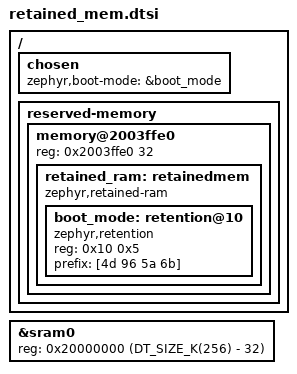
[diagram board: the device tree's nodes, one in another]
/*
 * Copyright (c) Arduino s.r.l. and/or its affiliated companies
 *
 * SPDX-License-Identifier: Apache-2.0
 */

/*
 * Warm-reset retained RAM shared by MCUboot and the loader/sketch; both
 * overlays in this directory include it, so the addresses cannot drift.
 *
 *   0x00  double-tap cookie, MCUboot only (boot/arduino/hooks/hooks.c)
 *   0x10  boot_mode, set by a double tap or the 1200-bps touch and consumed
 *         by CONFIG_BOOT_USB_DFU_BOOT_MODE
 *
 * sram0 is shrunk by the region's size so neither image's linker allocates
 * into it; outside .bss and .data it survives a warm reset.
 */
&sram0 {
	reg = <0x20000000 (DT_SIZE_K(256) - 32)>;
};

/ {
	chosen {
		zephyr,boot-mode = &boot_mode;
	};

	reserved-memory {
		#address-cells = <1>;
		#size-cells = <1>;
		ranges;

		memory@2003ffe0 {
			reg = <0x2003ffe0 32>;

			retained_ram: retainedmem {
				compatible = "zephyr,retained-ram";
				status = "okay";
				#address-cells = <1>;
				#size-cells = <1>;

				boot_mode: retention@10 {
					compatible = "zephyr,retention";
					status = "okay";
					reg = <0x10 0x5>;
					prefix = [4d 96 5a 6b];
				};
			};
		};
	};
};
